# STM32H730 register map
File version: 1.9
CPU: CM7 r0p1, little endian, MPU, FPU, 4 interrupt priority bits
Registers are 32-bit, read-write, reset 0x0 unless marked. A register's access mark holds for its fields unless they carry their own. Offsets are from the block's base; [hi:lo] are bit positions; {n}, {i} and the like mark numbered series; 'fields as' and 'values as' point back to an identical list.

## DMAMUX2 — DMAMUX
Base 0x58025800
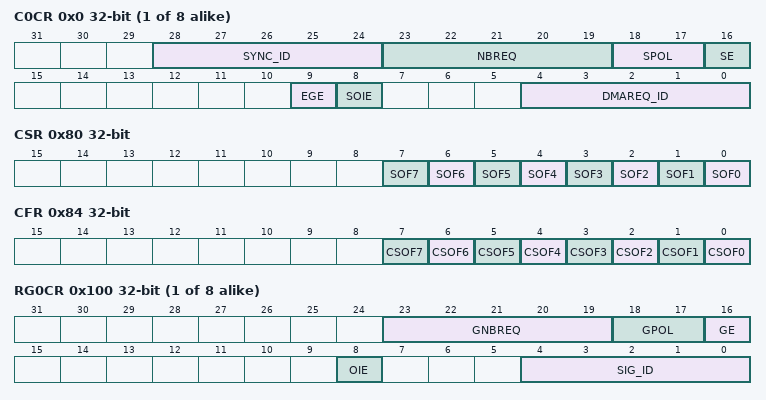
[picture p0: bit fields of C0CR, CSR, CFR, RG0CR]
{0x0+4i} C{i}CR (i=0..7) — DMAMux - DMA request line multiplexer channel x control register
  [28:24] SYNC_ID — Synchronization input selected
  [23:19] NBREQ — Number of DMA requests to forward Defines the number of DMA requests forwarded before output event is generated. In synchronous mode, it also defines the number of DMA requests to forward after a synchronization event, then stop forwarding. The actual number of DMA requests forwarded is NBREQ+1. Note: This field can only be written when both SE and EGE bits are reset.
  [18:17] SPOL — Synchronization event type selector Defines the synchronization event on the selected synchronization input:
  [16] SE — Synchronous operating mode enable/disable
  [9] EGE — Event generation enable/disable
  [8] SOIE — Interrupt enable at synchronization event overrun
  [4:0] DMAREQ_ID — Input DMA request line selected
0x80 CSR ro
  [n] SOF{n} (n=0..7) — Synchronization overrun event flag
0x84 CFR wo
  [n] CSOF{n} (n=0..7) — Clear synchronization overrun event flag Writing 1 in each bit clears the corresponding overrun flag SOFx in the DMAMUX_CSR register.
{0x100+4i} RG{i}CR (i=0..7) — DMAMux - DMA request generator channel x control register
  [23:19] GNBREQ — Number of DMA requests to generate Defines the number of DMA requests generated after a trigger event, then stop generating. The actual number of generated DMA requests is GNBREQ+1. Note: This field can only be written when GE bit is reset.
  [18:17] GPOL — DMA request generator trigger event type selection Defines the trigger event on the selected DMA request trigger input
  [16] GE — DMA request generator channel enable/disable
  [8] OIE — Interrupt enable at trigger event overrun
  [4:0] SIG_ID — DMA request trigger input selected
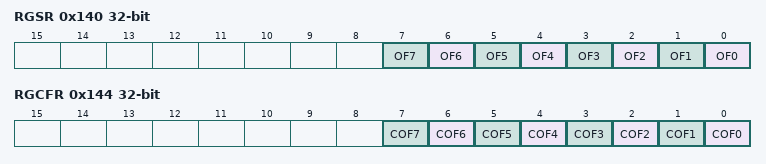
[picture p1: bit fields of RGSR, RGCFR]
0x140 RGSR ro
  [n] OF{n} (n=0..7) — Trigger overrun event flag
0x144 RGCFR ro
  [n] COF{n} (n=0..7) — Clear trigger overrun event flag

## HSEM
Base 0x58026400
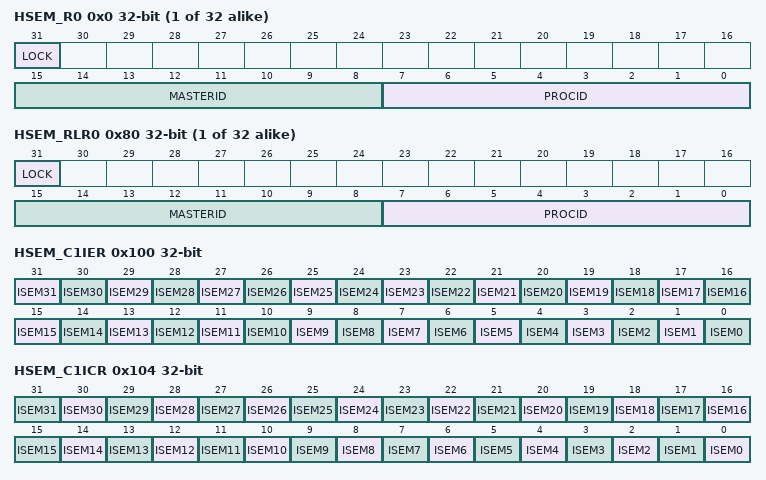
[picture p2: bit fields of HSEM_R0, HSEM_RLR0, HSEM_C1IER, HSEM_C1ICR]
{0x0+4i} HSEM_R{i} (i=0..31) — HSEM register HSEM_R0 HSEM_R31
  [31] LOCK — Lock indication
  [15:8] MASTERID — Semaphore MasterID
  [7:0] PROCID — Semaphore ProcessID
{0x80+4i} HSEM_RLR{i} ro (i=0..31) — HSEM Read lock register
  fields as HSEM_R0
0x100 HSEM_C1IER — HSEM Interrupt enable register
  [31] ISEM31 — Interrupt(N) semaphore n enable bit.
  [n] ISEM{n} (n=0..30) — Interrupt semaphore n enable bit
0x104 HSEM_C1ICR ro — HSEM Interrupt clear register
  [n] ISEM{n} (n=0..31) — Interrupt(N) semaphore n clear bit
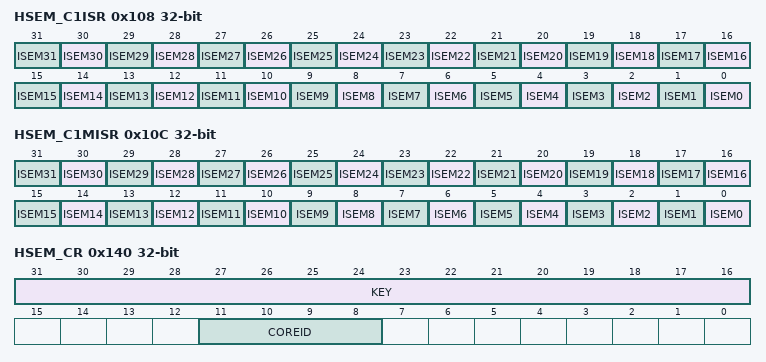
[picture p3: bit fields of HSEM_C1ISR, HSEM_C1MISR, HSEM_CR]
0x108 HSEM_C1ISR ro — HSEM Interrupt status register
  [n] ISEM{n} (n=0..31) — Interrupt(N) semaphore n status bit before enable (mask)
0x10C HSEM_C1MISR ro — HSEM Masked interrupt status register
  [n] ISEM{n} (n=0..31) — masked interrupt(N) semaphore n status bit after enable (mask)
0x140 HSEM_CR — HSEM Clear register
  [31:16] KEY — Semaphore clear Key
  [11:8] COREID — MasterID of semaphores to be cleared
0x144 HSEM_KEYR — HSEM Interrupt clear register
  [31:16] KEY — Semaphore Clear Key

## HASH — HASH address block description
Base 0x48021400
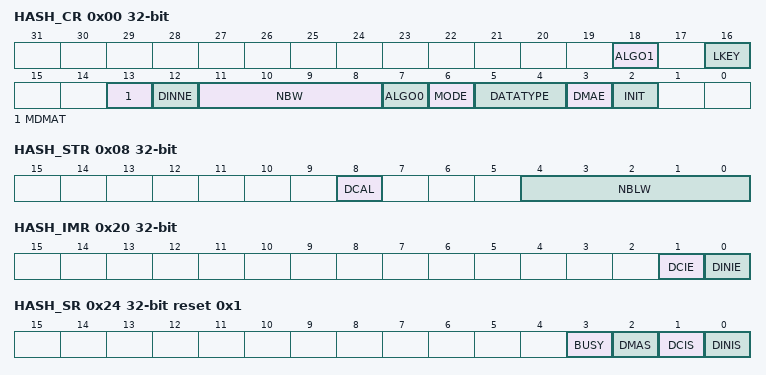
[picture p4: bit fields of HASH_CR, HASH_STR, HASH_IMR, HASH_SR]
0x00 HASH_CR — HASH control register
  [18] ALGO1 — Algorithm selection
    0=SHA-1; 1=MD5
  [16] LKEY — Long key selection
    0=the HMAC key is shorter or equal to 64 bytes; 1=the HMAC key is longer than 64 bytes
  [13] MDMAT — Multiple DMA transfers
    0=DCAL is automatically set at the end of a DMA transfer; 1=DCAL is not automatically set at the end of a DMA transfer
  [12] DINNE ro — DIN not empty
    0=No data are present in the data input buffer; 1=The input buffer contains at least one word of data
  [11:8] NBW ro — Number of words already pushed
    0=if DINNE=0, no word has been pushed into the DIN buffer (both HASH_DIN register and IN FIFO are empty), otherwise one word has been pushed into the DIN buffer (HASH_DIN register contains one word and IN FIFO is empty); 1=two words have been pushed into the DIN buffer (that is HASH_DIN register and the IN FIFO contain one word each); 15=16 words have been pushed into the DIN buffer
  [7] ALGO0 — Algorithm selection
    0=SHA-1; 1=MD5
  [6] MODE — Mode selection
    0=Hash mode selected; 1=HMAC mode selected
  [5:4] DATATYPE — Data type selection
    0=32-bit data; 1=16-bit data, or half-word; 2=8-bit data, or bytes; 3=bit data, or bit-string
  [3] DMAE — DMA enable
    0=DMA transfers disabled; 1=DMA transfers enabled
  [2] INIT — Initialize message digest calculation
0x04 HASH_DIN — HASH data input register
  [31:0] DATAIN — Data input
0x08 HASH_STR — HASH start register
  [8] DCAL — Digest calculation
  [4:0] NBLW — Number of valid bits in the last word
    0=All 32 bits of the last data written are valid message bits that is M[31:0]; 1=Only one bit of the last data written (after swapping) is valid that is M[0]; 2=Only two bits of the last data written (after swapping) are valid that is M[1:0]; 3=Only three bits of the last data written (after swapping) are valid that is M[2:0]; 31=Only 31 bits of the last data written (after swapping) are valid that is M[30:0]
{0xC+4i} HASH_HRA{i} ro (i=0..4) — HASH aliased digest register {i}
  [31:0] H{i} — Hash data x
0x20 HASH_IMR — HASH interrupt enable register
  [1] DCIE — Digest calculation completion interrupt enable
    0=Digest calculation completion interrupt disabled; 1=Digest calculation completion interrupt enabled
  [0] DINIE — Data input interrupt enable
    0=Data input interrupt disabled; 1=Data input interrupt enabled
0x24 HASH_SR reset 0x1 — HASH status register
  [3] BUSY ro — Busy bit
    0=No block is currently being processed; 1=The hash core is processing a block of data
  [2] DMAS ro — DMA Status
    0=DMA interface is disabled (DMAE=0) and no transfer is ongoing; 1=DMA interface is enabled (DMAE=1) or a transfer is ongoing
  [1] DCIS — Digest calculation completion interrupt status
    0=No digest available in the HASH_HRx registers (zeros are returned); 1=Digest calculation complete, a digest is available in the HASH_HRx registers
  [0] DINIS — Data input interrupt status
    0=Less than 16 locations are free in the input buffer; 1=A new block can be entered into the input buffer
{0xF8+4i} HASH_CSR{i} (i=0..53) — HASH context swap register {i}
  [31:0] CS{i} — Context swap x
{0x310+4i} HASH_HR{i} ro (i=0..4) — HASH digest register {i}
  [31:0] H{i} — Hash data x
{0x310+4i} HASH_HR{i} ro (i=5..7) — HASH supplementary digest register {i}
  [31:0] H{i} — Hash data x
